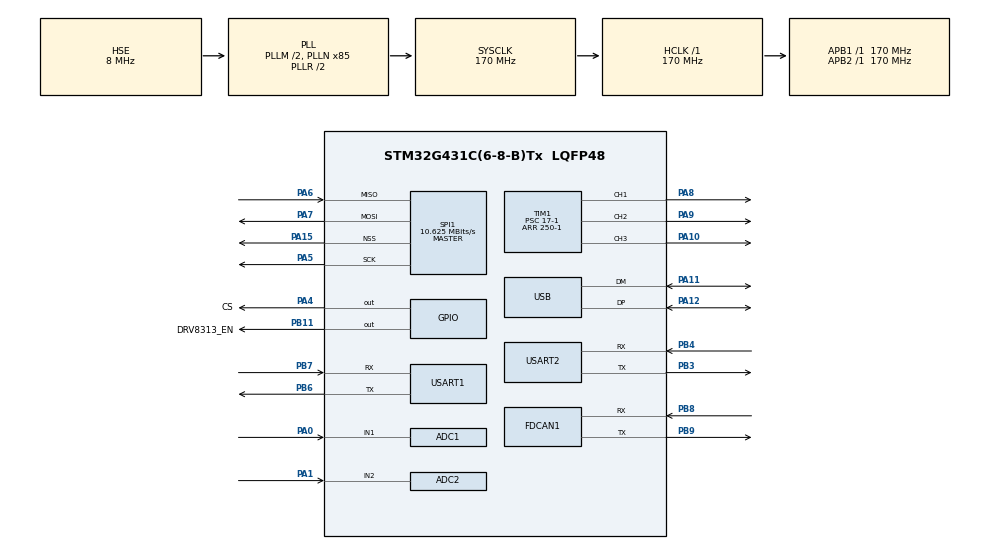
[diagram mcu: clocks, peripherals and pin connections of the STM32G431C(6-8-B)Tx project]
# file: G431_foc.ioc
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ADC1.EnableInjectedConversion=ENABLE
ADC1.EnableInjectedOversampling=ENABLE
ADC1.EnableRegularConversion=DISABLE
ADC1.ExternalTrigInjecConv=ADC_EXTERNALTRIGINJEC_T1_CC4
ADC1.InjNumberOfConversion=1
ADC1.InjOversamplingRightShift=ADC_RIGHTBITSHIFT_1
ADC1.InjectedChannel-1\#ChannelInjectedConversion=ADC_CHANNEL_1
ADC1.InjectedOffsetNumber-1\#ChannelInjectedConversion=ADC_OFFSET_NONE
ADC1.InjectedRank-1\#ChannelInjectedConversion=1
ADC1.InjectedSamplingTime-1\#ChannelInjectedConversion=ADC_SAMPLETIME_6CYCLES_5
ADC1.Mode=ADC_DUALMODE_INJECSIMULT
ADC1.Rank1_Channel=ADC_CHANNEL_1
ADC1.master=1
ADC2.EnableInjectedConversion=ENABLE
ADC2.EnableInjectedOversampling=ENABLE
ADC2.EnableRegularConversion=DISABLE
ADC2.InjNumberOfConversion=1
ADC2.InjOversamplingRightShift=ADC_RIGHTBITSHIFT_1
ADC2.InjectedChannel-1\#ChannelInjectedConversion=ADC_CHANNEL_2
ADC2.InjectedOffsetNumber-1\#ChannelInjectedConversion=ADC_OFFSET_NONE
ADC2.InjectedRank-1\#ChannelInjectedConversion=1
ADC2.InjectedSamplingTime-1\#ChannelInjectedConversion=ADC_SAMPLETIME_6CYCLES_5
ADC2.Mode=ADC_DUALMODE_INJECSIMULT
ADC2.Rank1_Channel=ADC_CHANNEL_2
Dma.Request0=USART1_RX
Dma.Request1=USART1_TX
Dma.USART1_RX.0.Direction=DMA_PERIPH_TO_MEMORY
Dma.USART1_RX.0.EventEnable=DISABLE
Dma.USART1_RX.0.Instance=DMA1_Channel1
Dma.USART1_RX.0.MemDataAlignment=DMA_MDATAALIGN_BYTE
Dma.USART1_RX.0.MemInc=DMA_MINC_ENABLE
Dma.USART1_RX.0.Mode=DMA_NORMAL
Dma.USART1_RX.0.PeriphDataAlignment=DMA_PDATAALIGN_BYTE
Dma.USART1_RX.0.PeriphInc=DMA_PINC_DISABLE
Dma.USART1_RX.0.Polarity=HAL_DMAMUX_REQ_GEN_RISING
Dma.USART1_RX.0.Priority=DMA_PRIORITY_LOW
Dma.USART1_RX.0.RequestNumber=1
Dma.USART1_RX.0.SignalID=NONE
Dma.USART1_RX.0.SyncEnable=DISABLE
Dma.USART1_RX.0.SyncPolarity=HAL_DMAMUX_SYNC_NO_EVENT
Dma.USART1_RX.0.SyncRequestNumber=1
Dma.USART1_RX.0.SyncSignalID=NONE
Dma.USART1_TX.1.Direction=DMA_MEMORY_TO_PERIPH
Dma.USART1_TX.1.EventEnable=DISABLE
Dma.USART1_TX.1.Instance=DMA1_Channel2
Dma.USART1_TX.1.MemDataAlignment=DMA_MDATAALIGN_BYTE
Dma.USART1_TX.1.MemInc=DMA_MINC_ENABLE
Dma.USART1_TX.1.Mode=DMA_NORMAL
Dma.USART1_TX.1.PeriphDataAlignment=DMA_PDATAALIGN_BYTE
Dma.USART1_TX.1.PeriphInc=DMA_PINC_DISABLE
Dma.USART1_TX.1.Polarity=HAL_DMAMUX_REQ_GEN_RISING
Dma.USART1_TX.1.Priority=DMA_PRIORITY_LOW
Dma.USART1_TX.1.RequestNumber=1
Dma.USART1_TX.1.SignalID=NONE
Dma.USART1_TX.1.SyncEnable=DISABLE
Dma.USART1_TX.1.SyncPolarity=HAL_DMAMUX_SYNC_NO_EVENT
Dma.USART1_TX.1.SyncRequestNumber=1
Dma.USART1_TX.1.SyncSignalID=NONE
FDCAN1.AutoRetransmission=ENABLE
FDCAN1.CalculateBaudRateNominal=500000
FDCAN1.CalculateTimeBitNominal=2000
FDCAN1.CalculateTimeQuantumNominal=100.0
FDCAN1.NominalPrescaler=17
FDCAN1.NominalTimeSeg1=16
FDCAN1.NominalTimeSeg2=3
Mcu.Family=STM32G4
Mcu.Name=STM32G431C(6-8-B)Tx
Mcu.Package=LQFP48
NVIC.ADC1_2_IRQn=true\:0\:0\:false\:false\:true\:true\:true\:true
NVIC.DMA1_Channel1_IRQn=true\:1\:0\:true\:false\:true\:false\:true\:true
NVIC.DMA1_Channel2_IRQn=true\:1\:0\:true\:false\:true\:false\:true\:true
NVIC.FDCAN1_IT0_IRQn=true\:1\:0\:true\:false\:true\:true\:true\:true
NVIC.FDCAN1_IT1_IRQn=true\:1\:0\:true\:false\:true\:true\:true\:true
NVIC.PriorityGroup=NVIC_PRIORITYGROUP_4
NVIC.SPI1_IRQn=true\:1\:0\:true\:false\:true\:true\:true\:true
NVIC.TIM6_DAC_IRQn=true\:1\:0\:true\:false\:true\:true\:true\:true
NVIC.USART1_IRQn=true\:1\:0\:true\:false\:true\:true\:true\:true
NVIC.USB_LP_IRQn=true\:1\:0\:true\:false\:true\:false\:true\:true
PA0.Mode=IN1-Single-Ended
PA0.Signal=ADC1_IN1
PA1.Mode=IN2-Single-Ended
PA1.Signal=ADC2_IN2
PA10.Signal=S_TIM1_CH3
PA11.Mode=Device
PA11.Signal=USB_DM
PA12.Mode=Device
PA12.Signal=USB_DP
PA13.Mode=Serial_Wire
PA13.Signal=SYS_JTMS-SWDIO
PA14.Mode=Serial_Wire
PA14.Signal=SYS_JTCK-SWCLK
PA15.Mode=NSS_Signal_Hard_Output
PA15.Signal=SPI1_NSS
PA4.GPIO_Label=CS
PA4.GPIO_PuPd=GPIO_PULLUP
PA4.GPIO_Speed=GPIO_SPEED_FREQ_VERY_HIGH
PA4.PinState=GPIO_PIN_SET
PA4.Signal=GPIO_Output
PA5.Mode=Full_Duplex_Master
PA5.Signal=SPI1_SCK
PA6.Mode=Full_Duplex_Master
PA6.Signal=SPI1_MISO
PA7.Mode=Full_Duplex_Master
PA7.Signal=SPI1_MOSI
PA8.Signal=S_TIM1_CH1
PA9.Signal=S_TIM1_CH2
PB11.GPIO_Label=DRV8313_EN
PB11.GPIO_Speed=GPIO_SPEED_FREQ_VERY_HIGH
PB11.Signal=GPIO_Output
PB3.Mode=Asynchronous
PB3.Signal=USART2_TX
PB4.Mode=Asynchronous
PB4.Signal=USART2_RX
PB6.Mode=Asynchronous
PB6.Signal=USART1_TX
PB7.Mode=Asynchronous
PB7.Signal=USART1_RX
PB8-BOOT0.Mode=FDCAN_Activate
PB8-BOOT0.Signal=FDCAN1_RX
PB9.Mode=FDCAN_Activate
PB9.Signal=FDCAN1_TX
PF0-OSC_IN.Mode=HSE-External-Oscillator
PF0-OSC_IN.Signal=RCC_OSC_IN
PF1-OSC_OUT.Mode=HSE-External-Oscillator
PF1-OSC_OUT.Signal=RCC_OSC_OUT
ProjectManager.HeapSize=0x200
ProjectManager.StackSize=0x400
ProjectManager.TargetToolchain=MDK-ARM V5.32
RCC.ADC12Freq_Value=170000000
RCC.AHBFreq_Value=170000000
RCC.APB1Freq_Value=170000000
RCC.APB1TimFreq_Value=170000000
RCC.APB2Freq_Value=170000000
RCC.APB2TimFreq_Value=170000000
RCC.CK48CLockSelection=RCC_USBCLKSOURCE_HSI48
RCC.CortexFreq_Value=170000000
RCC.EXTERNAL_CLOCK_VALUE=12288000
RCC.HCLKFreq_Value=170000000
RCC.HSE_VALUE=8000000
RCC.HSI48_VALUE=48000000
RCC.HSI_VALUE=16000000
RCC.LSE_VALUE=32768
RCC.PLLM=RCC_PLLM_DIV2
RCC.PLLN=85
RCC.PLLQ=RCC_PLLQ_DIV4
RCC.PLLSourceVirtual=RCC_PLLSOURCE_HSE
RCC.SYSCLKFreq_VALUE=170000000
RCC.SYSCLKSource=RCC_SYSCLKSOURCE_PLLCLK
RCC.USBFreq_Value=48000000
RCC.VCOOutputFreq_Value=340000000
SH.S_TIM1_CH1.0=TIM1_CH1,PWM Generation1 CH1
SH.S_TIM1_CH2.0=TIM1_CH2,PWM Generation2 CH2
SH.S_TIM1_CH3.0=TIM1_CH3,PWM Generation3 CH3
SPI1.BaudRatePrescaler=SPI_BAUDRATEPRESCALER_16
SPI1.CLKPhase=SPI_PHASE_2EDGE
SPI1.CLKPolarity=SPI_POLARITY_HIGH
SPI1.CalculateBaudRate=10.625 MBits/s
SPI1.DataSize=SPI_DATASIZE_16BIT
SPI1.Direction=SPI_DIRECTION_2LINES
SPI1.Mode=SPI_MODE_MASTER
SPI1.VirtualNSS=VM_NSSHARD
SPI1.VirtualType=VM_MASTER
TIM1.AutoReloadPreload=TIM_AUTORELOAD_PRELOAD_ENABLE
TIM1.Channel-PWM\ Generation1\ CH1=TIM_CHANNEL_1
TIM1.Channel-PWM\ Generation2\ CH2=TIM_CHANNEL_2
TIM1.Channel-PWM\ Generation3\ CH3=TIM_CHANNEL_3
TIM1.Channel-PWM\ Generation4\ No\ Output=TIM_CHANNEL_4
TIM1.CounterMode=TIM_COUNTERMODE_CENTERALIGNED1
TIM1.OCMode_PWM-PWM\ Generation1\ CH1=TIM_OCMODE_PWM2
TIM1.OCMode_PWM-PWM\ Generation2\ CH2=TIM_OCMODE_PWM2
TIM1.OCMode_PWM-PWM\ Generation3\ CH3=TIM_OCMODE_PWM2
TIM1.PeriodNoDither=250-1
TIM1.Prescaler=17-1
TIM1.PulseNoDither_1=125
TIM1.PulseNoDither_2=125
TIM1.PulseNoDither_3=125
TIM1.PulseNoDither_4=249
TIM1.TIM_MasterOutputTrigger=TIM_TRGO_UPDATE
TIM6.AutoReloadPreload=TIM_AUTORELOAD_PRELOAD_ENABLE
TIM6.PeriodNoDither=1000-1
TIM6.Prescaler=170-1
USART1.VirtualMode-Asynchronous=VM_ASYNC
USART2.VirtualMode-Asynchronous=VM_ASYNC
USB_DEVICE.CLASS_NAME_FS=CDC
USB_DEVICE.VirtualMode=Cdc
USB_DEVICE.VirtualModeFS=Cdc_FS
VP_RCC_VS_USB.Mode=USB_FS
VP_SYS_VS_DBSignals.Mode=DisableDeadBatterySignals
VP_TIM1_VS_ClockSourceINT.Mode=Internal
VP_TIM1_VS_no_output4.Mode=PWM Generation4 No Output
VP_TIM6_VS_ClockSourceINT.Mode=Enable_Timer
VP_USB_DEVICE_VS_USB_DEVICE_CDC_FS.Mode=CDC_FS
board=custom

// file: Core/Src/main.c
/* USER CODE BEGIN Header */
/**
  ******************************************************************************
  * @file           : main.c
  * @brief          : Main program body
  ******************************************************************************
  * @attention
  *
  * Copyright (c) 2026 STMicroelectronics.
  * All rights reserved.
  *
  * This software is licensed under terms that can be found in the LICENSE file
  * in the root directory of this software component.
  * If no LICENSE file comes with this software, it is provided AS-IS.
  *
  ******************************************************************************
  */
/* USER CODE END Header */
#include "main.h"
#include "adc.h"
#include "dma.h"
#include "fdcan.h"
#include "spi.h"
#include "tim.h"
#include "usart.h"
#include "usb_device.h"
#include "gpio.h"

/* USER CODE BEGIN Includes */
#include "my_main.h"
/* USER CODE END Includes */

void SystemClock_Config(void);

int main(void)
{

  /* USER CODE BEGIN 1 */
//  SCB->VTOR = 0x08000000;//BOOT0û����Ҫ�����λ�ж�������
//    __DSB();
//    __ISB();
//    __enable_irq();
  /* USER CODE END 1 */

  /* MCU Configuration--------------------------------------------------------*/

  /* Reset of all peripherals, Initializes the Flash interface and the Systick. */
  HAL_Init();

  /* Configure the system clock */
  SystemClock_Config();

  /* Initialize all configured peripherals */
  MX_GPIO_Init();
  MX_DMA_Init();
  MX_ADC1_Init();
  MX_ADC2_Init();
  MX_FDCAN1_Init();
  MX_SPI1_Init();
  MX_TIM1_Init();
  MX_USART1_UART_Init();
  MX_USART2_UART_Init();
  MX_TIM6_Init();
  MX_USB_Device_Init();
  /* USER CODE BEGIN 2 */
	my_main();
  /* USER CODE END 2 */

  /* Infinite loop */
  while (1)
  {

  }
}

void SystemClock_Config(void)
{
  RCC_OscInitTypeDef RCC_OscInitStruct = {0};
  RCC_ClkInitTypeDef RCC_ClkInitStruct = {0};
  RCC_CRSInitTypeDef pInit = {0};

  /** Configure the main internal regulator output voltage
  */
  HAL_PWREx_ControlVoltageScaling(PWR_REGULATOR_VOLTAGE_SCALE1_BOOST);

  /** Initializes the RCC Oscillators according to the specified parameters
  * in the RCC_OscInitTypeDef structure.
  */
  RCC_OscInitStruct.OscillatorType = RCC_OSCILLATORTYPE_HSI48|RCC_OSCILLATORTYPE_HSE;
  RCC_OscInitStruct.HSEState = RCC_HSE_ON;
  RCC_OscInitStruct.HSI48State = RCC_HSI48_ON;
  RCC_OscInitStruct.PLL.PLLState = RCC_PLL_ON;
  RCC_OscInitStruct.PLL.PLLSource = RCC_PLLSOURCE_HSE;
  RCC_OscInitStruct.PLL.PLLM = RCC_PLLM_DIV2;
  RCC_OscInitStruct.PLL.PLLN = 85;
  RCC_OscInitStruct.PLL.PLLP = RCC_PLLP_DIV2;
  RCC_OscInitStruct.PLL.PLLQ = RCC_PLLQ_DIV4;
  RCC_OscInitStruct.PLL.PLLR = RCC_PLLR_DIV2;
  if (HAL_RCC_OscConfig(&RCC_OscInitStruct) != HAL_OK)
  {
    Error_Handler();
  }

  /** Initializes the CPU, AHB and APB buses clocks
  */
  RCC_ClkInitStruct.ClockType = RCC_CLOCKTYPE_HCLK|RCC_CLOCKTYPE_SYSCLK
                              |RCC_CLOCKTYPE_PCLK1|RCC_CLOCKTYPE_PCLK2;
  RCC_ClkInitStruct.SYSCLKSource = RCC_SYSCLKSOURCE_PLLCLK;
  RCC_ClkInitStruct.AHBCLKDivider = RCC_SYSCLK_DIV1;
  RCC_ClkInitStruct.APB1CLKDivider = RCC_HCLK_DIV1;
  RCC_ClkInitStruct.APB2CLKDivider = RCC_HCLK_DIV1;

  if (HAL_RCC_ClockConfig(&RCC_ClkInitStruct, FLASH_LATENCY_4) != HAL_OK)
  {
    Error_Handler();
  }

  /** Enable the SYSCFG APB clock
  */
  __HAL_RCC_CRS_CLK_ENABLE();

  /** Configures CRS
  */
  pInit.Prescaler = RCC_CRS_SYNC_DIV1;
  pInit.Source = RCC_CRS_SYNC_SOURCE_USB;
  pInit.Polarity = RCC_CRS_SYNC_POLARITY_RISING;
  pInit.ReloadValue = __HAL_RCC_CRS_RELOADVALUE_CALCULATE(48000000,1000);
  pInit.ErrorLimitValue = 34;
  pInit.HSI48CalibrationValue = 32;

  HAL_RCCEx_CRSConfig(&pInit);
}

void Error_Handler(void)
{
  __disable_irq();
  while (1)
  {
  }
}
